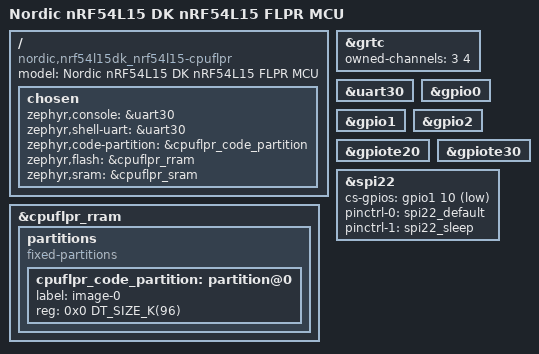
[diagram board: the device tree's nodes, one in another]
/*
 * Copyright (c) 2024 Nordic Semiconductor ASA
 *
 * SPDX-License-Identifier: Apache-2.0
 */

/dts-v1/;
#include <vendor/nordic/nrf54l15_cpuflpr.dtsi>
#include "nrf54l15dk_common.dtsi"

/ {
	model = "Nordic nRF54L15 DK nRF54L15 FLPR MCU";
	compatible = "nordic,nrf54l15dk_nrf54l15-cpuflpr";

	chosen {
		zephyr,console = &uart30;
		zephyr,shell-uart = &uart30;
		zephyr,code-partition = &cpuflpr_code_partition;
		zephyr,flash = &cpuflpr_rram;
		zephyr,sram = &cpuflpr_sram;
	};
};

&cpuflpr_rram {
	partitions {
		compatible = "fixed-partitions";
		#address-cells = <1>;
		#size-cells = <1>;
		ranges;

		cpuflpr_code_partition: partition@0 {
			label = "image-0";
			reg = <0x0 DT_SIZE_K(96)>;
		};
	};
};

&grtc {
	owned-channels = <3 4>;
	status = "okay";
};

&uart30 {
	status = "okay";
};

&gpio0 {
	status = "okay";
};

&gpio1 {
	status = "okay";
};

&gpio2 {
	status = "okay";
};

&gpiote20 {
	status = "okay";
};

&gpiote30 {
	status = "okay";
};

/*
 * Note this SPI instance conflicts with UART30. Disable or reconfigure pinctrl for UART30
 * to use this SPI instance.
 */
nordic_expansion_spi: &spi22 {
	cs-gpios = <&gpio1 10 GPIO_ACTIVE_LOW>;
	pinctrl-0 = <&spi22_default>;
	pinctrl-1 = <&spi22_sleep>;
	pinctrl-names = "default", "sleep";
};
